AUTOSAR XML (schema 00049)
package /Interfaces
  5 x sender receiver interface:
    VehicleSpeed_I
      data VehicleSpeed: type=VehicleSpeed_T
    EngineSpeed_I
      data EngineSpeed
      data EngineSpeedValid
    ThrottlePosition_I
      data ThrottlePosition
    GearPosition_I
      data Gear
    BrakePressure_I
      data BrakePressure
  client server interface DiagnosticService_I
    operation ReadDtc
    operation ClearDtc
package /Components/Powertrain
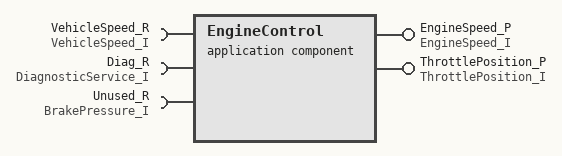
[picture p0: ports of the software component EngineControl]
  application sw component type EngineControl
    provide port EngineSpeed_P: provided-interface=EngineSpeed_I
    provide port ThrottlePosition_P: provided-interface=ThrottlePosition_I
    require port VehicleSpeed_R: required-interface=VehicleSpeed_I
    require port Diag_R: required-interface=DiagnosticService_I
    require port Unused_R: required-interface=BrakePressure_I
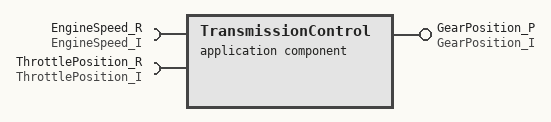
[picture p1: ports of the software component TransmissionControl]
  application sw component type TransmissionControl
    require port EngineSpeed_R: required-interface=EngineSpeed_I
    require port ThrottlePosition_R: required-interface=ThrottlePosition_I
    provide port GearPosition_P: provided-interface=GearPosition_I
package /Components/Chassis
  application sw component type WheelSpeedSensor
    provide port VehicleSpeed_P: provided-interface=VehicleSpeed_I
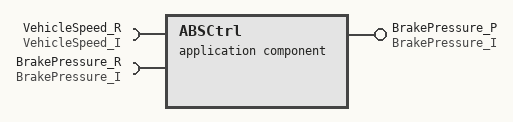
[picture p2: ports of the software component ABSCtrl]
  application sw component type ABSCtrl
    require port VehicleSpeed_R: required-interface=VehicleSpeed_I
    require port BrakePressure_R: required-interface=BrakePressure_I
    provide port BrakePressure_P: provided-interface=BrakePressure_I
  application sw component type BrakeActuator
    require port BrakePressure_R: required-interface=BrakePressure_I
package /Components/Services
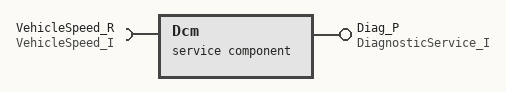
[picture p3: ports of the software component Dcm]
  service sw component type Dcm
    provide port Diag_P: provided-interface=DiagnosticService_I
    require port VehicleSpeed_R: required-interface=VehicleSpeed_I
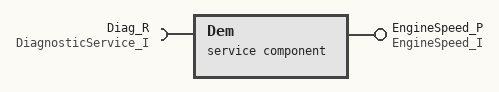
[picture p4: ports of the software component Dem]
  service sw component type Dem
    provide port EngineSpeed_P: provided-interface=EngineSpeed_I
    require port Diag_R: required-interface=DiagnosticService_I
package /Compositions
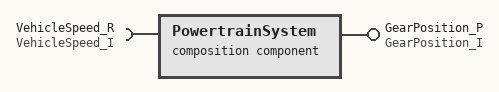
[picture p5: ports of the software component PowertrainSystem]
  composition sw component type PowertrainSystem
    provide port GearPosition_P: provided-interface=GearPosition_I
    require port VehicleSpeed_R: required-interface=VehicleSpeed_I
    component Engine: type=EngineControl
    component Transmission: type=TransmissionControl
    connect Engine.EngineSpeed_P -> Transmission.EngineSpeed_R
    connect Engine.ThrottlePosition_P -> Transmission.ThrottlePosition_R
package /Vehicle
  composition sw component type VehicleTop
    6 x component:
      Powertrain: type=PowertrainSystem
      WheelSpeedSensorInst: type=WheelSpeedSensor
      ABS: type=ABSCtrl
      Brake: type=BrakeActuator
      DcmInst: type=Dcm
      DemInst: type=Dem
    connect WheelSpeedSensorInst.VehicleSpeed_P -> ABS.VehicleSpeed_R
    connect ABS.BrakePressure_P -> Brake.BrakePressure_R
    connect WheelSpeedSensorInst.VehicleSpeed_P -> DcmInst.VehicleSpeed_R
    connect DcmInst.Diag_P -> DemInst.Diag_R
    connect DemInst.EngineSpeed_P -> ABS.BrakePressure_R
    delegate VehicleSpeed_R <-> outer port PowertrainSystem/VehicleSpeed_R
